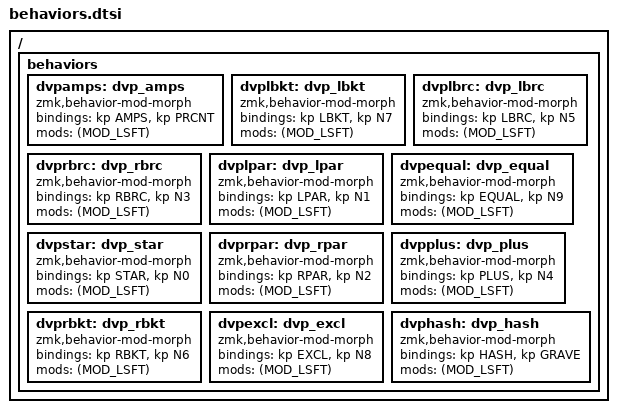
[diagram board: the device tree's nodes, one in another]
/ {
    behaviors {
        dvpamps: dvp_amps {
            compatible = "zmk,behavior-mod-morph";
            #binding-cells = <0>;
            bindings = <&kp AMPS>, <&kp PRCNT>;
            mods = <(MOD_LSFT)>;
        };
        dvplbkt: dvp_lbkt {
            compatible = "zmk,behavior-mod-morph";
            #binding-cells = <0>;
            bindings = <&kp LBKT>, <&kp N7>;
            mods = <(MOD_LSFT)>;
        };
        dvplbrc: dvp_lbrc {
            compatible = "zmk,behavior-mod-morph";
            #binding-cells = <0>;
            bindings = <&kp LBRC>, <&kp N5>;
            mods = <(MOD_LSFT)>;
        };
        dvprbrc: dvp_rbrc {
            compatible = "zmk,behavior-mod-morph";
            #binding-cells = <0>;
            bindings = <&kp RBRC>, <&kp N3>;
            mods = <(MOD_LSFT)>;
        };
        dvplpar: dvp_lpar {
            compatible = "zmk,behavior-mod-morph";
            #binding-cells = <0>;
            bindings = <&kp LPAR>, <&kp N1>;
            mods = <(MOD_LSFT)>;
        };
        dvpequal: dvp_equal {
            compatible = "zmk,behavior-mod-morph";
            #binding-cells = <0>;
            bindings = <&kp EQUAL>, <&kp N9>;
            mods = <(MOD_LSFT)>;
        };
        dvpstar: dvp_star {
            compatible = "zmk,behavior-mod-morph";
            #binding-cells = <0>;
            bindings = <&kp STAR>, <&kp N0>;
            mods = <(MOD_LSFT)>;
        };
        dvprpar: dvp_rpar {
            compatible = "zmk,behavior-mod-morph";
            #binding-cells = <0>;
            bindings = <&kp RPAR>, <&kp N2>;
            mods = <(MOD_LSFT)>;
        };
        dvpplus: dvp_plus {
            compatible = "zmk,behavior-mod-morph";
            #binding-cells = <0>;
            bindings = <&kp PLUS>, <&kp N4>;
            mods = <(MOD_LSFT)>;
        };
        dvprbkt: dvp_rbkt {
            compatible = "zmk,behavior-mod-morph";
            #binding-cells = <0>;
            bindings = <&kp RBKT>, <&kp N6>;
            mods = <(MOD_LSFT)>;
        };
        dvpexcl: dvp_excl {
            compatible = "zmk,behavior-mod-morph";
            #binding-cells = <0>;
            bindings = <&kp EXCL>, <&kp N8>;
            mods = <(MOD_LSFT)>;
        };
        dvphash: dvp_hash {
            compatible = "zmk,behavior-mod-morph";
            #binding-cells = <0>;
            bindings = <&kp HASH>, <&kp GRAVE>;
            mods = <(MOD_LSFT)>;
        };
    };
};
